# file9 register map
Vendor: Test Ltd.; Series: TestSeries; File version: 1.1
Test svd file with cluster, dimArrayIndex and sauRegionsConfig
CPU: CM33 r0p0, little endian, MPU, no FPU, VTOR, 3 interrupt priority bits, 5 interrupts, 2 SAU regions
Registers are 32-bit, read-write, reset 0x0 unless marked. A register's access mark holds for its fields unless they carry their own. Offsets are from the block's base; lines under a group give offsets from that group; [hi:lo] are bit positions; {n}, {i} and the like mark numbered series; 'fields as' and 'values as' point back to an identical list; <NAME> marks a mode.

## Memory map
0x40003000 TestClusterPeripheral — Test peripheral with a register cluster

## TestClusterPeripheral — Test peripheral with a register cluster
Base 0x40003000
0x00 CH0 group — Channel 0 register set
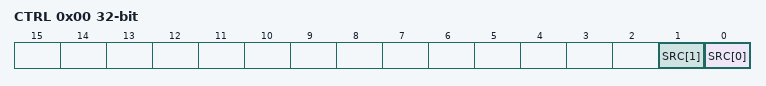
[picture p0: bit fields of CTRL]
  0x00 CTRL — Channel control register
    [n] SRC[{n}] (n=0..1) — Source select, indexed field

## Licence text in the file
MIT License
